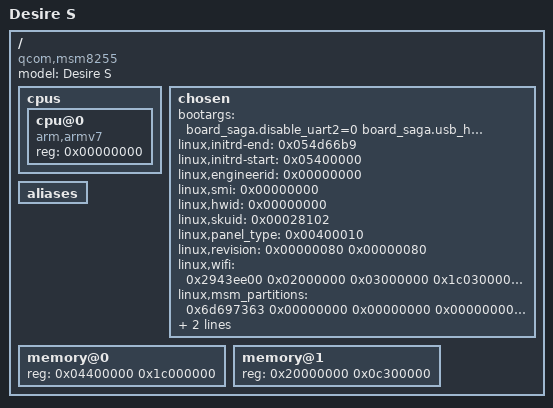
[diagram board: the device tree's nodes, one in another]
/dts-v1/;

/ {
	model = "Desire S";
	compatible = "qcom,msm8255";
	#address-cells = <0x00000001>;
	#size-cells = <0x00000001>;

	cpus {
		#address-cells = <0x00000001>;
		#size-cells = <0x00000000>;
		cpu@0 {
			device_type = "cpu";
			compatible = "arm,armv7";
			reg = <0x00000000>;
		};
	};

	chosen {
		bootargs = "board_saga.disable_uart2=0 board_saga.usb_h2w_sw=0 board_saga.disable_sdcard=0 diag.enabled=0 board_saga.debug_uart=0 smisize=0 userdata_sel=0 androidboot.emmc=true androidboot.pagesize=4096 ats=0  androidboot.lb=1 androidboot.baseband=3831.19.00.110 androidboot.cid=11111111 androidboot.batt_poweron=good_battery androidboot.carrier=ALL androidboot.mid=PG88***** androidboot.keycaps=qwerty androidboot.mode=normal androidboot.serialno=SH153TJ00870 androidboot.bootloader=2.02.0002 zygote_oneshot=off msm_watchdog.enable=1 kmemleak=off no_console_suspend=1 androidboot.selinux=permissive androidboot.hardware=htc7x30";
		linux,initrd-end = <0x054d66b9>;
		linux,initrd-start = <0x05400000>;
		linux,engineerid = <0x00000000>;
		linux,smi = <0x00000000>;
		linux,hwid = <0x00000000>;
		linux,skuid = <0x00028102>;
		linux,panel_type = <0x00400010>;
		linux,revision = <0x00000080 0x00000080>;
		linux,wifi = <0x2943ee00 0x02000000 0x03000000 0x1c030000 0xf49ccf1e 0x00000000 0x00000000 0x00000000 0x00000000 0x30000000 0x00000000 0x00000000 0x00000000 0x00000000 0x00000000 0x00000000 0x6d616361 0x6464723d 0x36343a41 0x373a3639 0x3a41393a 0x45323a35 0x330d0d0a 0x73726f6d 0x7265763d 0x330d0d0a 0x76656e64 0x69643d30 0x78313465 0x340d0d0a 0x64657669 0x643d3078 0x34333266 0x0d0d0a62 0x6f617264 0x74797065 0x3d307834 0x62390d0d 0x0a626f61 0x72647265 0x763d3078 0x33360d0d 0x0a626f61 0x7264666c 0x6167733d 0x30783230 0x300d0d0a 0x7874616c 0x66726571 0x3d333734 0x30300d0d 0x0a616132 0x673d310d 0x0d0a6161 0x35673d30 0x0d0d0a61 0x67303d32 0x35350d0d 0x0a706130 0x62303d34 0x3938342c 0x34393834 0x2c353037 0x340d0d0a 0x70613062 0x313d3634 0x3332382c 0x36343332 0x382c3634 0x3330350d 0x0d0a7061 0x3062323d 0x36353139 0x342c3635 0x3139342c 0x36353139 0x370d0d0a 0x70613069 0x74737369 0x743d3632 0x0d0d0a70 0x61306d61 0x78707772 0x3d37380d 0x0d0a6f66 0x646d706f 0x3d307841 0x41414141 0x4141410d 0x0d0a6d63 0x73326770 0x6f303d30 0x78414141 0x410d0d0a 0x6d637332 0x67706f31 0x3d307841 0x4141410d 0x0d0a7273 0x7369736d 0x6632673d 0x3078612c 0x3078612c 0x3078610d 0x0d0a7273 0x7369736d 0x6332673d 0x3078622c 0x3078622c 0x3078610d 0x0d0a7273 0x73697361 0x7632673d 0x3078332c 0x3078332c 0x3078330d 0x0d0a7263 0x616c5f66 0x6c61673d 0x30783631 0x0d0d0a62 0x78613267 0x3d300d0d 0x0a63636f 0x64653d41 0x4c4c0d0d 0x0a636374 0x6c3d3078 0x300d0d0a 0x63636b64 0x69676669 0x6c747479 0x70653d30 0x0d0d0a6f 0x66646d64 0x69676669 0x6c747479 0x70653d31 0x0d0d0a72 0x78706f32 0x673d300d 0x0d0a626f 0x6172646e 0x756d3d31 0x0d0d0a6e 0x6f637263 0x3d310d0d 0x0a6f7470 0x696d6167 0x6573697a 0x653d3138 0x320d0d0a 0x68776864 0x723d3078 0x30356666 0x66663033 0x31303330 0x30333130 0x30333130 0x30303030 0x0d0d0a52 0x4157313d 0x38302033 0x32206665 0x20323120 0x30322030 0x63203030 0x20323220 0x32612030 0x31203031 0x20303020 0x30302063 0x35203020 0x65362030 0x30203030 0x20303020 0x30302030 0x30203430 0x20303020 0x30302066 0x66206666 0x20383020 0x30302030 0x30203030 0x20303020 0x30302030 0x30203030 0x20303020 0x30302030 0x30206338 0x20303020 0x30302030 0x30203030 0x20303020 0x30302030 0x30203030 0x20303020 0x30302030 0x30203030 0x20303020 0x66662032 0x30203034 0x20443020 0x32203239 0x20343320 0x32312030 0x32203063 0x20303020 0x32322030 0x34203030 0x20323020 0x30302035 0x410d0d0a 0x73645f67 0x706f7574 0x3d300d0d 0x0a73645f 0x6f6f626f 0x6e6c793d 0x310d0d0a 0x72737369 0x5f6f6666 0x7365743d 0x300d0d0a 0x00000000 0x00000000 0x00000000 0x00000000 0x00000000 0x00000000 0x00000000 0x00000000 0x00000000 0x00000000 0x00000000 0x00000000 0x00000000 0x00000000 0x00000000 0x00000000 0x00000000 0x00000000 0x00000000 0x00000000 0x00000000 0x00000000 0x00000000 0x00000000 0x00000000 0x00000000 0x00000000 0x00000000 0x00000000 0x00000000 0x00000000 0x00000000 0x00000000 0x00000000 0x00000000 0x00000000 0x00000000 0x00000000 0x00000000 0x00000000 0x00000000 0x00000000 0x00000000 0x00000000 0x00000000 0x00000000 0x00000000 0x00000000 0x00000000 0x00000000 0x00000000 0x00000000 0x00000000 0x00000000 0x00000000 0x00000000 0x00000000 0x00000000 0x00000000 0x00000000 0x00000000 0x00000000 0x00000000 0x00000000 0x00000000 0x00000000 0x00000000 0x00000000 0x00000000 0x00000000 0x00000000 0x00000000 0x00000000 0x00000000 0x00000000 0x00000000 0x00000000 0x00000000 0x00000000 0x00000000 0x00000000 0x00000000 0x00000000 0x00000000 0x00000000 0x00000000 0x00000000 0x00000000 0x00000000 0x00000000 0x00000000 0x00000000 0x00000000 0x00000000 0x00000000 0x00000000 0x00000000 0x00000000 0x00000000 0x00000000 0x00000000 0x00000000 0x00000000 0x00000000 0x00000000 0x00000000 0x00000000 0x00000000 0x00000000 0x00000000 0x00000000 0x00000000 0x00000000 0x00000000 0x00000000 0x00000000 0x00000000 0x00000000 0x00000000 0x00000000 0x00000000 0x00000000 0x00000000 0x00000000 0x00000000 0x00000000 0x00000000 0x00000000 0x00000000 0x00000000 0x00000000 0x00000000 0x00000000 0x00000000 0x00000000 0x00000000 0x00000000 0x00000000 0x00000000 0x00000000 0x00000000 0x00000000 0x00000000 0x00000000 0x00000000 0x00000000 0x00000000 0x00000000 0x00000000 0x00000000 0x00000000 0x00000000 0x00000000 0x00000000 0x00000000 0x00000000 0x00000000 0x00000000 0x00000000 0x00000000 0x00000000 0x00000000 0x00000000 0x00000000 0x00000000 0x00000000 0x00000000 0x00000000 0x00000000 0x00000000 0x00000000 0x00000000 0x00000000 0x00000000 0x00000000 0x00000000 0x00000000 0x00000000 0x00000000 0x00000000 0x00000000 0x00000000 0x00000000 0x00000000 0x00000000 0x00000000 0x00000000 0x00000000 0x00000000 0x00000000 0x00000000 0x00000000 0x00000000 0x00000000 0x00000000 0x00000000 0x00000000 0x00000000 0x00000000 0x00000000 0x00000000 0x00000000 0x00000000 0x00000000 0x00000000 0x00000000 0x00000000 0x00000000 0x00000000 0x00000000 0x00000000 0x00000000 0x00000000 0x00000000 0x00000000 0x00000000 0x00000000 0x00000000 0x00000000 0x00000000 0x00000000 0x00000000 0x00000000 0x00000000 0x00000000 0x00000000 0x00000000 0x00000000 0x00000000 0x00000000 0x00000000 0x00000000 0x00000000 0x00000000 0x00000000 0x00000000 0x00000000 0x00000000 0x00000000 0x00000000 0x00000000 0x00000000 0x00000000 0x00000000 0x00000000 0x00000000 0x00000000 0x00000000 0x00000000 0x00000000 0x00000000 0x00000000 0x00000000 0x00000000 0x00000000 0x00000000 0x00000000 0x00000000 0x00000000 0x00000000 0x00000000 0x00000000 0x00000000 0x00000000 0x00000000 0x00000000 0x00000000 0x00000000 0x00000000 0x00000000 0x00000000 0x00000000 0x00000000 0x00000000 0x00000000 0x00000000 0x00000000 0x00000000 0x00000000 0x00000000 0x00000000 0x00000000 0x00000000 0x00000000 0x00000000 0x00000000 0x00000000 0x00000000>;
		linux,msm_partitions = <0x6d697363 0x00000000 0x00000000 0x00000000 0x11000000 0x00020000 0x00000000 0x7265636f 0x76657279 0x00000000 0x00000000 0x15000000 0xfa430000 0x00000000 0x626f6f74 0x00000000 0x00000000 0x00000000 0x16000000 0x00200000 0x00000000 0x73797374 0x656d0000 0x00000000 0x00000000 0x19000000 0xff6f1100 0x00000000 0x6c6f6361 0x6c000000 0x00000000 0x00000000 0x1e000000 0xfe170000 0x00000000 0x63616368 0x65000000 0x00000000 0x00000000 0x1b000000 0x7e870400 0x00000000 0x75736572 0x64617461 0x00000000 0x00000000 0x1a000000 0xffb72400 0x00000000 0x6465766c 0x6f670000 0x00000000 0x00000000 0x1f000000 0xffa50000 0x00000000 0x70646174 0x61000000 0x00000000 0x00000000 0x20000000 0x00020000 0x00000000 0x6c696200 0x00000000 0x00000000 0x00000000 0x1d000000 0x00c00400 0x00000000 0x65787472 0x61000000 0x00000000 0x00000000 0x1c000000 0x80000000 0x00000000>;
		linux,ps_type = <0x00000000>;
		linux,pcbid = <0x00000000>;
	};

	aliases {
	};

	memory@0 {
		device_type = "memory";
		reg = <0x04400000 0x1c000000>;
	};

	memory@1 {
		device_type = "memory";
		reg = <0x20000000 0x0c300000>;
	};
};
